# platform_designer_hps_system_hps_0_hps register map
Vendor: default_vendor.com; File version: 0.0
Registers are 32-bit, read-write, reset 0x0 unless marked. A register's access mark holds for its fields unless they carry their own. Offsets are from the block's base; [hi:lo] are bit positions; {n}, {i} and the like mark numbered series; 'fields as' and 'values as' point back to an identical list.

## sysmgr (part 1 of 3) — Registers in the System Manager module
Base 0xFFD08000
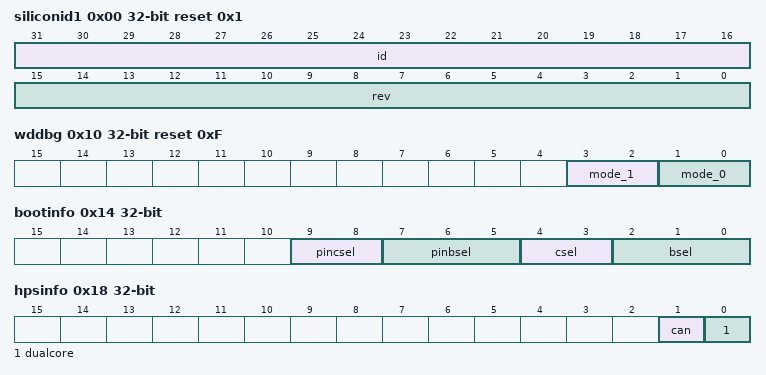
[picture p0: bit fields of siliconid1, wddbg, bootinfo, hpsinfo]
0x00 siliconid1 ro reset 0x1 — Specifies Silicon ID and revision number.
  [31:16] id — Silicon ID
    0=HPS_CycloneV_ArriaV
  [15:0] rev — Silicon revision number.
0x04 siliconid2 ro — Reserved for future use.
  [31:0] rsv
0x10 wddbg reset 0xF — Controls the behavior of the L4 watchdogs when the CPUs are in debug mode. These control registers are used to drive the pause input signal of the L4 watchdogs. Note that the watchdogs built into the MPU automatically are paused when their associated CPU enters debug mode. Only reset by a cold reset.
  [3:2] mode_1 — Controls behavior of L4 watchdog when CPUs in debug mode. Field array index matches L4 watchdog index.
    0=Continue; 1=PauseCPU0; 2=PauseCPU1; 3=PauseEither
  [1:0] mode_0 — Controls behavior of L4 watchdog when CPUs in debug mode. Field array index matches L4 watchdog index.
    0=Continue; 1=PauseCPU0; 2=PauseCPU1; 3=PauseEither
0x14 bootinfo ro (reset mask 0xFFFE0000) — Provides access to boot configuration information.
  [9:8] pincsel — Specifies the sampled value of the HPS CSEL pins. The value of HPS CSEL pins are sampled upon deassertion of cold reset.
  [7:5] pinbsel — Specifies the sampled value of the HPS BSEL pins. The value of HPS BSEL pins are sampled upon deassertion of cold reset.
  [4:3] csel — The clock select field specifies clock information for booting. The clock select encoding is a function of the CSEL value. The clock select field is read by the Boot ROM code on a cold or warm reset when booting from a flash device to get information about how to setup the HPS clocking to boot from the specified clock device. The encoding of the clock select field is specified by the enum associated with this field. The HPS CSEL pins value are sampled upon deassertion of cold reset.
  [2:0] bsel — The boot select field specifies the boot source. It is read by the Boot ROM code on a cold or warm reset to determine the boot source. The HPS BSEL pins value are sampled upon deassertion of cold reset.
    1=FPGA; 2=NAND_Flash_1_8v; 3=NAND_Flash_3_0v; 4=SD_MMC_EXTERNAL_TRANSCEIVER_1_8v; 5=SD_MMC_INTERNAL_TRANSCEIVER_3_0v; 6=QSPI_Flash_1_8v; 7=QSPI_Flash_3_0v
0x18 hpsinfo ro (reset mask 0xFFFFFFFC) — Provides information about the HPS capabilities.
  [1] can — Indicates if CAN0 and CAN1 controllers are available or not.
    0=CAN_UNAVAILABLE; 1=CAN_AVAILABLE
  [0] dualcore — Indicates if CPU1 is available in MPU or not.
    0=SingleCore; 1=DualCore
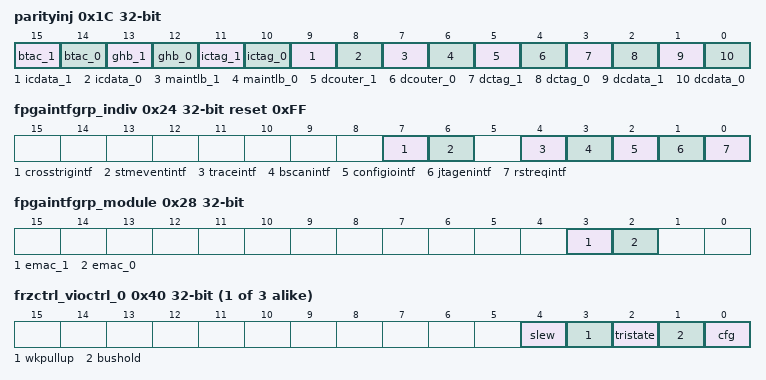
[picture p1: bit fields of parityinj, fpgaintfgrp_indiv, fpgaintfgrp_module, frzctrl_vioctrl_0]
0x1C parityinj — Inject parity failures into the parity-protected RAMs in the MPU. Allows software to test the parity failure interrupt handler. The field array index corresponds to the CPU index. All fields are reset by a cold or warm reset.
  [15] btac_1 — If 1, injecting parity error to BTAC RAM.The field array index corresponds to the CPU index.
  [14] btac_0 — If 1, injecting parity error to BTAC RAM.The field array index corresponds to the CPU index.
  [13] ghb_1 — If 1, injecting parity error to GHB RAM.The field array index corresponds to the CPU index.
  [12] ghb_0 — If 1, injecting parity error to GHB RAM.The field array index corresponds to the CPU index.
  [11] ictag_1 — If 1, injecting parity error to Instruction Cache Tag RAM.The field array index corresponds to the CPU index.
  [10] ictag_0 — If 1, injecting parity error to Instruction Cache Tag RAM.The field array index corresponds to the CPU index.
  [9] icdata_1 — If 1, injecting parity error to Instruction Cache Data RAM.The field array index corresponds to the CPU index.
  [8] icdata_0 — If 1, injecting parity error to Instruction Cache Data RAM.The field array index corresponds to the CPU index.
  [7] maintlb_1 — If 1, injecting parity error to Main TLB RAM.The field array index corresponds to the CPU index.
  [6] maintlb_0 — If 1, injecting parity error to Main TLB RAM.The field array index corresponds to the CPU index.
  [5] dcouter_1 — If 1, injecting parity error to Data Cache Outer RAM.The field array index corresponds to the CPU index.
  [4] dcouter_0 — If 1, injecting parity error to Data Cache Outer RAM.The field array index corresponds to the CPU index.
  [3] dctag_1 — If 1, injecting parity error to Data Cache Tag RAM.The field array index corresponds to the CPU index.
  [2] dctag_0 — If 1, injecting parity error to Data Cache Tag RAM.The field array index corresponds to the CPU index.
  [1] dcdata_1 — If 1, injecting parity error to Data Cache Data RAM.The field array index corresponds to the CPU index.
  [0] dcdata_0 — If 1, injecting parity error to Data Cache Data RAM.The field array index corresponds to the CPU index.
0x20 fpgaintfgrp_gbl reset 0x1 — Used to disable all interfaces between the FPGA and HPS.
  [0] intf — Used to disable all interfaces between the FPGA and HPS. Software must ensure that all interfaces between the FPGA and HPS are inactive before disabling them.
    0=Disable; 1=Enable
0x24 fpgaintfgrp_indiv reset 0xFF — Used to disable individual interfaces between the FPGA and HPS.
  [all] fields
    0=Disable; 1=Enable
  [7] crosstrigintf — Used to disable the FPGA Fabric from sending triggers to HPS debug logic. Note that this doesn't prevent the HPS debug logic from sending triggers to the FPGA Fabric.
  [6] stmeventintf — Used to disable the STM event interface. This interface allows logic in the FPGA fabric to trigger events to the STM debug module in the HPS.
  [4] traceintf — Used to disable the trace interface. This interface allows the HPS debug logic to send trace data to logic in the FPGA fabric.
  [3] bscanintf — Used to disable the boundary-scan interface. This interface allows the FPGA JTAG TAP controller to execute boundary-scan instructions such as SAMPLE/PRELOAD, EXTEST, and HIGHZ. The boundary-scan interface must be enabled before attempting to send the boundary-scan instructions to the FPGA JTAG TAP controller.
  [2] configiointf — Used to disable the CONFIG_IO interface. This interface allows the FPGA JTAG TAP controller to execute the CONFIG_IO instruction and configure all device I/Os (FPGA and HPS). This is typically done before executing boundary-scan instructions. The CONFIG_IO interface must be enabled before attempting to send the CONFIG_IO instruction to the FPGA JTAG TAP controller.
  [1] jtagenintf — Used to disable the JTAG enable interface. This interface allows logic in the FPGA fabric to disable the HPS JTAG operation.
  [0] rstreqintf — Used to disable the reset request interface. This interface allows logic in the FPGA fabric to request HPS resets. This field disables the following reset request signals from the FPGA fabric to HPS:[list][*]f2h_cold_rst_req_n - Triggers a cold reset of the HPS[*]f2h_warm_rst_req_n - Triggers a warm reset of the HPS[*]f2h_dbg_rst_req_n - Triggers a debug reset of the HPS[/list]
0x28 fpgaintfgrp_module — Used to disable signals from the FPGA fabric to individual HPS modules.
  [3] emac_1 — Used to disable signals from the FPGA fabric to the EMAC modules that could potentially interfere with their normal operation. The array index corresponds to the EMAC module instance.
    0=Disable; 1=Enable
  [2] emac_0 — Used to disable signals from the FPGA fabric to the EMAC modules that could potentially interfere with their normal operation. The array index corresponds to the EMAC module instance.
    0=Disable; 1=Enable
0x30 scanmgrgrp_ctrl — Controls behaviors of Scan Manager not controlled by registers in the Scan Manager itself.
  [0] fpgajtagen — Controls whether FPGA JTAG pins or Scan Manager drives JTAG signals to the FPGA. Only reset by a cold reset (ignores warm reset).
    0=Fpgapins; 1=Scanmgr
{0x40+4i} frzctrl_vioctrl_{i} (i=0..2) — Used to drive freeze signals to HPS VIO banks. The register array index corresponds to the freeze channel. Freeze channel 0 provides freeze signals to VIO bank 0 and 1. Freeze channel 1 provides freeze signals to VIO bank 2 and 3. Only drives freeze signals when SRC.VIO1 is set to SW. Freeze channel 2 provides freeze signals to VIO bank 4. All fields are only reset by a cold reset (ignore warm reset). The following equation determines when the weak pullup resistor is enabled: enabled = ~wkpullup | (CFF & cfg & tristate) where CFF is the value of weak pullup as set by IO configuration
  [4] slew — Controls IO slew-rate
    0=Slow; 1=Cfg
  [3] wkpullup — Controls weak pullup resistor
    0=Enable; 1=Cfg
  [2] tristate — Controls IO tri-state
    0=Enable; 1=Cfg
  [1] bushold — Controls bus hold circuit
    0=Disable; 1=Cfg
  [0] cfg — Controls IO configuration
    0=Disable; 1=Cfg
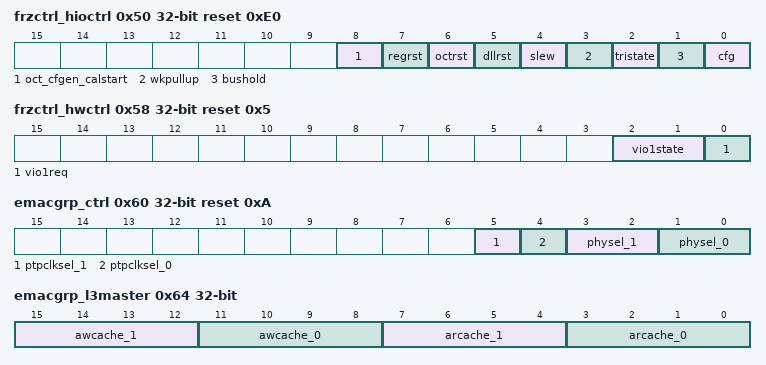
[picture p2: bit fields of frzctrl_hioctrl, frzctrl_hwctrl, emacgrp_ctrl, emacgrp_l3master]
0x50 frzctrl_hioctrl reset 0xE0 — Used to drive freeze signals to HPS HIO bank (DDR SDRAM). All fields are only reset by a cold reset (ignore warm reset). The following equation determines when the weak pullup resistor is enabled: enabled = ~wkpullup | (CFF & cfg & tristate) where CFF is the value of weak pullup as set by IO configuration
  [8] oct_cfgen_calstart — Controls OCT calibration and OCT IO configuration enable.
    0=Disable; 1=Enable
  [7] regrst — Controls IO and DQS reset.
    0=Disable; 1=Enable
  [6] octrst — Controls OCT reset.
    0=Disable; 1=Enable
  [5] dllrst — Controls DLL (Delay-Locked Loop) reset.
    0=Disable; 1=Enable
  [4] slew — Controls IO slew-rate
    0=Slow; 1=Cfg
  [3] wkpullup — Controls weak pullup resistor
    0=Enable; 1=Cfg
  [2] tristate — Controls IO tri-state
    0=Enable; 1=Cfg
  [1] bushold — Controls bus hold circuit
    0=Disable; 1=Cfg
  [0] cfg — Controls IO configuration
    0=Disable; 1=Cfg
0x54 frzctrl_src — Contains register field to choose between software state machine (vioctrl array index [1] register) or hardware state machine in the Freeze Controller as the freeze signal source for VIO channel 1. All fields are only reset by a cold reset (ignore warm reset).
  [0] vio1 — The freeze signal source for VIO channel 1 (VIO bank 2 and bank 3).
    0=sw; 1=hw
0x58 frzctrl_hwctrl reset 0x5 — Activate freeze or thaw operations on VIO channel 1 (HPS IO bank 2 and bank 3) and monitor for completeness and the current state. These fields interact with the hardware state machine in the Freeze Controller. These fields can be accessed independent of the value of SRC1.VIO1 although they only have an effect on the VIO channel 1 freeze signals when SRC1.VIO1 is setup to have the hardware state machine be the freeze signal source. All fields are only reset by a cold reset (ignore warm reset).
  [2:1] vio1state ro — Software reads this field to determine the current frozen/thawed state of the VIO channel 1 or to determine when a freeze/thaw request is made by writing the corresponding *REQ field in this register has completed. Reset by a cold reset (ignores warm reset).
    0=Thawed2Frozen; 1=Thawed; 2=Frozen; 3=Frozen2Thawed
  [0] vio1req — Requests hardware state machine to generate freeze signal sequence to transition between frozen and thawed states. If this field is read by software, it contains the value previously written by software (i.e. this field is not written by hardware).
    0=ReqThaw; 1=ReqFrz
0x60 emacgrp_ctrl reset 0xA — Registers used by the EMACs. All fields are reset by a cold or warm reset.
  [5] ptpclksel_1 — Selects the source of the 1588 PTP reference clock. This is sampled by an EMAC module when it exits from reset. The field array index corresponds to the EMAC index.
    0=OSC1_CLK; 1=FPGA_PTP_REF_CLK
  [4] ptpclksel_0 — Selects the source of the 1588 PTP reference clock. This is sampled by an EMAC module when it exits from reset. The field array index corresponds to the EMAC index.
    0=OSC1_CLK; 1=FPGA_PTP_REF_CLK
  [3:2] physel_1 — Controls the PHY interface selection of the EMACs. This is sampled by an EMAC module when it exits from reset. The associated enum defines the allowed values. The field array index corresponds to the EMAC index.
    0=GMII_MII; 1=RGMII; 2=RMII
  [1:0] physel_0 — Controls the PHY interface selection of the EMACs. This is sampled by an EMAC module when it exits from reset. The associated enum defines the allowed values. The field array index corresponds to the EMAC index.
    0=GMII_MII; 1=RGMII; 2=RMII
0x64 emacgrp_l3master — Controls the L3 master ARCACHE and AWCACHE AXI signals. These register bits should be updated only during system initialization prior to removing the peripheral from reset. They may not be changed dynamically during peripheral operation All fields are reset by a cold or warm reset.
  [all] fields
    0=Noncache_Nonbuff; 1=Buff; 2=Cache_Nonalloc; 3=Cache_Buff_Nonalloc; 6=Cache_Wrthru_Rdalloc; 7=Cache_Wrback_Rdalloc; 10=Cache_Wrthru_Wralloc; 11=Cache_Wrback_Wralloc; 14=Cache_Wrthru_Alloc; 15=Cache_Wrback_Alloc
  [15:12] awcache_1 — Specifies the values of the 2 EMAC AWCACHE signals. The field array index corresponds to the EMAC index.
  [11:8] awcache_0 — Specifies the values of the 2 EMAC AWCACHE signals. The field array index corresponds to the EMAC index.
  [7:4] arcache_1 — Specifies the values of the 2 EMAC ARCACHE signals. The field array index corresponds to the EMAC index.
  [3:0] arcache_0 — Specifies the values of the 2 EMAC ARCACHE signals. The field array index corresponds to the EMAC index.
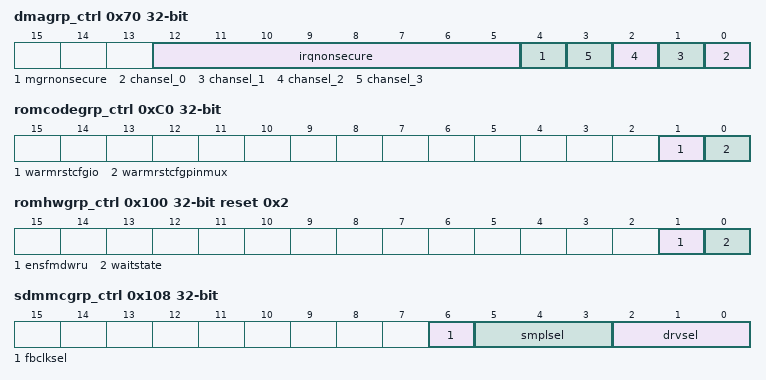
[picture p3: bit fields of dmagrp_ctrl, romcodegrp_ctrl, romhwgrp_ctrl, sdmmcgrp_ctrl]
0x70 dmagrp_ctrl — Registers used by the DMA Controller. All fields are reset by a cold or warm reset. These register bits should be updated during system initialization prior to removing the DMA controller from reset. They may not be changed dynamically during DMA operation.
  [12:5] irqnonsecure — Specifies the security state of an event-interrupt resource. If bit index [x] is 0, the DMAC assigns event<x> or irq[x] to the Secure state. If bit index [x] is 1, the DMAC assigns event<x> or irq[x] to the Non-secure state.
  [4] mgrnonsecure — Specifies the security state of the DMA manager thread. 0 = assigns DMA manager to the Secure state. 1 = assigns DMA manager to the Non-secure state. Sampled by the DMA controller when it exits from reset.
  [n] chansel_{n} (n=0..3) — Controls mux that selects whether FPGA or CAN connects to one of the DMA peripheral request interfaces.The peripheral request interface index equals the array index + 4. For example, array index 0 is for peripheral request index 4.
    0=FPGA; 1=CAN
0x74 dmagrp_persecurity — Controls the security state of a peripheral request interface. Sampled by the DMA controller when it exits from reset. These register bits should be updated during system initialization prior to removing the DMA controller from reset. They may not be changed dynamically during DMA operation.
  [31:0] nonsecure — If bit index [x] is 0, the DMA controller assigns peripheral request interface x to the Secure state. If bit index [x] is 1, the DMA controller assigns peripheral request interface x to the Non-secure state. Reset by a cold or warm reset.
{0x80+4i} iswgrp_handoff_{i} (i=0..7) — These registers are used to store handoff infomation between the preloader and the OS. These 8 registers can be used to store any information. The contents of these registers have no impact on the state of the HPS hardware.
  [31:0] value — Preloader Handoff Information.
0xC0 romcodegrp_ctrl — Contains information used to control Boot ROM code.
  [1] warmrstcfgio — Specifies whether the Boot ROM code configures the IOs used by boot after a warm reset. Note that the Boot ROM code always configures the IOs used by boot after a cold reset. After the Boot ROM code configures the IOs used by boot, it always disables this field. It is up to user software to enable this field if it wants a different behavior.
    0=disabled; 1=enabled
  [0] warmrstcfgpinmux — Specifies whether the Boot ROM code configures the pin mux for boot pins after a warm reset. Note that the Boot ROM code always configures the pin mux for boot pins after a cold reset. After the Boot ROM code configures the pin mux for boot pins, it always disables this field. It is up to user software to enable this field if it wants a different behavior.
    0=disabled; 1=enabled
0xC4 romcodegrp_cpu1startaddr — When CPU1 is released from reset and the Boot ROM is located at the CPU1 reset exception address (the typical case), the Boot ROM reset handler code reads the address stored in this register and jumps it to hand off execution to user software.
  [31:0] value — Address for CPU1 to start executing at after coming out of reset.
0xC8 romcodegrp_initswstate — The preloader software (loaded by the Boot ROM) writes the magic value 0x49535756 (ISWV in ASCII) to this register when it has reached a valid state.
  [31:0] value — Written with magic value.
    0=Invalid; 0x49535756=Valid
0xCC romcodegrp_initswlastld — Contains the index of the last preloader software image loaded by the Boot ROM from the boot device.
  [1:0] index — Index of last image loaded.
0xD0 romcodegrp_bootromswstate — 32-bits general purpose register used by the Boot ROM code. Actual usage is defined in the Boot ROM source code.
  [31:0] value — Reserved for Boot ROM use.
0xE0 romcodegrp_warmramgrp_enable — Enables or disables the warm reset from On-chip RAM feature.
  [31:0] magic — Controls whether Boot ROM will attempt to boot from the contents of the On-chip RAM on a warm reset. When this feature is enabled, the Boot ROM code will not configure boot IOs, the pin mux, or clocks. Note that the enable value is a 32-bit magic value (provided by the enum).
    0=disabled; 0xAE9EFEBC=enabled
0xE4 romcodegrp_warmramgrp_datastart — Offset into On-chip RAM of the start of the region for CRC validation
  [15:0] offset — Contains the byte offset into the On-chip RAM of the start of the On-chip RAM region for the warm boot CRC validation. The offset must be an integer multiple of 4 (i.e. aligned to a word). The Boot ROM code will set the top 16 bits to 0xFFFF and clear the bottom 2 bits.
0xE8 romcodegrp_warmramgrp_length — Length of region in On-chip RAM for CRC validation.
  [15:0] size — Contains the length (in bytes) of the region in the On-chip RAM for the warm boot CRC validation. If the length is 0, the Boot ROM won't perform CRC calculation and CRC check to avoid overhead caused by CRC validation. If the START + LENGTH exceeds the maximum offset into the On-chip RAM, the Boot ROM won't boot from the On-chip RAM. The length must be an integer multiple of 4. The Boot ROM code will clear the top 16 bits and the bottom 2 bits.
0xEC romcodegrp_warmramgrp_execution — Offset into On-chip RAM to enter to on a warm boot.
  [15:0] offset — Contains the byte offset into the On-chip RAM that the Boot ROM will jump to if the CRC validation succeeds. The Boot ROM code will set the top 16 bits to 0xFFFF.
0xF0 romcodegrp_warmramgrp_crc reset 0xE763552A — Length of region in On-chip RAM for CRC validation.
  [31:0] expected — Contains the expected CRC of the region in the On-chip RAM.The Boot ROM code calculates the actual CRC for all bytes in the region specified by the DATA START an LENGTH registers. The contents of the EXECUTION register (after it has been read and modified by the Boot ROM code) is also included in the CRC calculation. The contents of the EXECUTION register is added to the CRC accumulator a byte at a time starting with the least significant byte. If the actual CRC doesn't match the expected CRC value in this register, the Boot ROM won't boot from the On-chip RAM. The CRC is a standard CRC32 with the polynomial: x^32 + x^26 + x^23 + x^22 + x^16 + x^12 + x^11 + x^10 + x^8 + x^7 + x^5 + x^4 + x^2 + x + 1 There is no reflection of the bits and the initial value of the remainder is 0xFFFFFFFF and the final value is exclusive ORed with 0xFFFFFFFF.
0x100 romhwgrp_ctrl reset 0x2 — Controls behavior of Boot ROM hardware. All fields are only reset by a cold reset (ignore warm reset).
  [1] ensfmdwru — Controls whether the wait state bit is updated upon deassertion of warm reset. This field is set on a cold reset.
    0=Disable; 1=Enable
  [0] waitstate — Controls the number of wait states applied to the Boot ROM's read operation. This field is cleared on a cold reset and optionally updated by hardware upon deassertion of warm reset.
    0=Disable; 1=Enable
0x108 sdmmcgrp_ctrl — Registers used by the SDMMC Controller. All fields are reset by a cold or warm reset.
  [6] fbclksel — Select which fb_clk to be used as cclk_in_sample. If 0, cclk_in_sample is driven by internal phase shifted cclk_in. If 1, cclk_in_sample is driven by fb_clk_in. No phase shifting is provided internally on cclk_in_sample. Note: Using the feedback clock (setting this bit to 1) is not a supported use model.
  [5:3] smplsel — Select which phase shift of the clock for cclk_in_sample.
    0=degrees0; 1=degrees45; 2=degrees90; 3=degrees135; 4=degrees180; 5=degrees225; 6=degrees270; 7=degrees315
  [2:0] drvsel — Select which phase shift of the clock for cclk_in_drv.
    values as smplsel
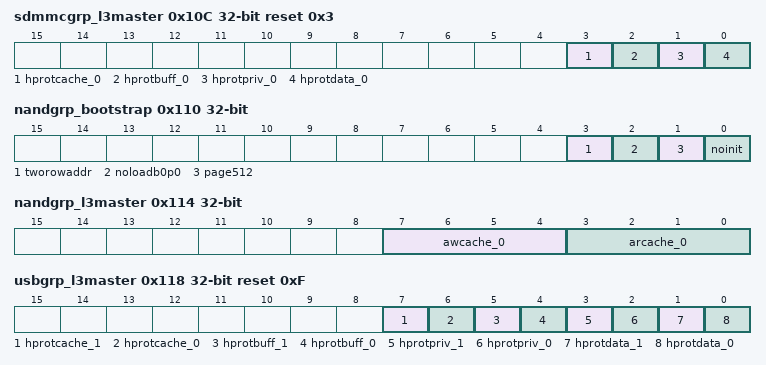
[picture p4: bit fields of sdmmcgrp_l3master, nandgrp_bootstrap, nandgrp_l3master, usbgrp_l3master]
0x10C sdmmcgrp_l3master reset 0x3 — Controls the L3 master HPROT AHB-Lite signal. These register bits should be updated only during system initialization prior to removing the peripheral from reset. They may not be changed dynamically during peripheral operation All fields are reset by a cold or warm reset.
  [3] hprotcache_0 — If 1, L3 master accesses for the SD/MMC module are cacheable.
  [2] hprotbuff_0 — If 1, L3 master accesses for the SD/MMC module are bufferable.
  [1] hprotpriv_0 — If 1, L3 master accesses for the SD/MMC module are privileged.
  [0] hprotdata_0 — Specifies if the L3 master access is for data or opcode for the SD/MMC module.
    0=Opcode; 1=Data
0x110 nandgrp_bootstrap — Bootstrap fields sampled by NAND Flash Controller when released from reset. All fields are reset by a cold or warm reset.
  [3] tworowaddr — If 1, NAND device requires only 2 row address cycles instead of the normal 3 row address cycles.
  [2] noloadb0p0 — If 1, inhibits NAND Flash Controller from loading page 0 of block 0 of the NAND device as part of the initialization procedure.
  [1] page512 — If 1, NAND device has a 512 byte page size.
  [0] noinit — If 1, inhibits NAND Flash Controller from performing initialization when coming out of reset. Instead, software must program all registers pertaining to device parameters like page size, width, etc.
0x114 nandgrp_l3master — Controls the L3 master ARCACHE and AWCACHE AXI signals. These register bits should be updated only during system initialization prior to removing the peripheral from reset. They may not be changed dynamically during peripheral operation All fields are reset by a cold or warm reset.
  [7:4] awcache_0 — Specifies the value of the module AWCACHE signal.
    values as the fields of emacgrp_l3master
  [3:0] arcache_0 — Specifies the value of the module ARCACHE signal.
    values as the fields of emacgrp_l3master
0x118 usbgrp_l3master reset 0xF — Controls the L3 master HPROT AHB-Lite signal. These register bits should be updated only during system initialization prior to removing the peripheral from reset. They may not be changed dynamically during peripheral operation All fields are reset by a cold or warm reset.
  [7] hprotcache_1 — If 1, L3 master accesses for the USB modules are cacheable. The field array index corresponds to the USB index.
  [6] hprotcache_0 — If 1, L3 master accesses for the USB modules are cacheable. The field array index corresponds to the USB index.
  [5] hprotbuff_1 — If 1, L3 master accesses for the USB modules are bufferable. The field array index corresponds to the USB index.
  [4] hprotbuff_0 — If 1, L3 master accesses for the USB modules are bufferable. The field array index corresponds to the USB index.
  [3] hprotpriv_1 — If 1, L3 master accesses for the USB modules are privileged. The field array index corresponds to the USB index.
  [2] hprotpriv_0 — If 1, L3 master accesses for the USB modules are privileged. The field array index corresponds to the USB index.
  [1] hprotdata_1 — Specifies if the L3 master access is for data or opcode for the USB modules. The field array index corresponds to the USB index.
    0=Opcode; 1=Data
  [0] hprotdata_0 — Specifies if the L3 master access is for data or opcode for the USB modules. The field array index corresponds to the USB index.
    0=Opcode; 1=Data
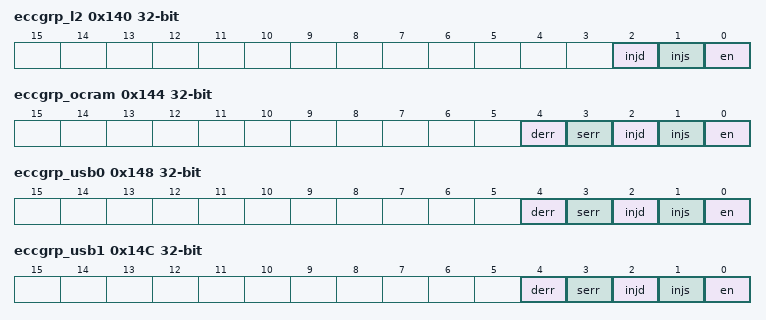
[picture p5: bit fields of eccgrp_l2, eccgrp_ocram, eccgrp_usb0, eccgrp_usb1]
0x140 eccgrp_l2 — This register is used to enable ECC on the L2 Data RAM. ECC errors can be injected into the write path using bits in this register. This register contains interrupt status of the ECC single/double bit error. Only reset by a cold reset (ignores warm reset).
  [2] injd — Changing this bit from zero to one injects a double, non-correctable error into the L2 Data RAM. This only injects one double bit error into the L2 Data RAM.
  [1] injs — Changing this bit from zero to one injects a single, correctable error into the L2 Data RAM. This only injects one error into the L2 Data RAM.
  [0] en — Enable ECC for L2 Data RAM
0x144 eccgrp_ocram — This register is used to enable ECC on the On-chip RAM. ECC errors can be injected into the write path using bits in this register. This register contains interrupt status of the ECC single/double bit error. Only reset by a cold reset (ignores warm reset).
  [4] derr write-1-clears — This bit is an interrupt status bit for On-chip RAM ECC double bit, non-correctable error. It is set by hardware when double bit, non-correctable error occurs in On-chip RAM. Software needs to write 1 into this bit to clear the interrupt status.
  [3] serr write-1-clears — This bit is an interrupt status bit for On-chip RAM ECC single, correctable error. It is set by hardware when single, correctable error occurs in On-chip RAM. Software needs to write 1 into this bit to clear the interrupt status.
  [2] injd — Changing this bit from zero to one injects a double, non-correctable error into the On-chip RAM. This only injects one double bit error into the On-chip RAM.
  [1] injs — Changing this bit from zero to one injects a single, correctable error into the On-chip RAM. This only injects one error into the On-chip RAM.
  [0] en — Enable ECC for On-chip RAM
0x148 eccgrp_usb0 — This register is used to enable ECC on the USB0 RAM. ECC errors can be injected into the write path using bits in this register. This register contains interrupt status of the ECC single/double bit error. Only reset by a cold reset (ignores warm reset).
  [4] derr write-1-clears — This bit is an interrupt status bit for USB0 RAM ECC double bit, non-correctable error. It is set by hardware when double bit, non-correctable error occurs in USB0 RAM. Software needs to write 1 into this bit to clear the interrupt status.
  [3] serr write-1-clears — This bit is an interrupt status bit for USB0 RAM ECC single, correctable error. It is set by hardware when single, correctable error occurs in USB0 RAM. Software needs to write 1 into this bit to clear the interrupt status.
  [2] injd — Changing this bit from zero to one injects a double, non-correctable error into the USB0 RAM. This only injects one double bit error into the USB0 RAM.
  [1] injs — Changing this bit from zero to one injects a single, correctable error into the USB0 RAM. This only injects one error into the USB0 RAM.
  [0] en — Enable ECC for USB0 RAM
0x14C eccgrp_usb1 — This register is used to enable ECC on the USB1 RAM. ECC errors can be injected into the write path using bits in this register. This register contains interrupt status of the ECC single/double bit error. Only reset by a cold reset (ignores warm reset).
  [4] derr write-1-clears — This bit is an interrupt status bit for USB1 RAM ECC double bit, non-correctable error. It is set by hardware when double bit, non-correctable error occurs in USB1 RAM. Software needs to write 1 into this bit to clear the interrupt status.
  [3] serr write-1-clears — This bit is an interrupt status bit for USB1 RAM ECC single, correctable error. It is set by hardware when single, correctable error occurs in USB1 RAM. Software needs to write 1 into this bit to clear the interrupt status.
  [2] injd — Changing this bit from zero to one injects a double, non-correctable error into the USB1 RAM. This only injects one double bit error into the USB1 RAM.
  [1] injs — Changing this bit from zero to one injects a single, correctable error into the USB1 RAM. This only injects one error into the USB1 RAM.
  [0] en — Enable ECC for USB1 RAM
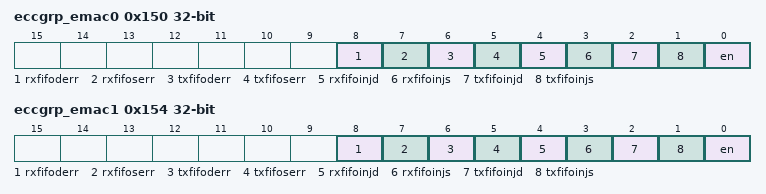
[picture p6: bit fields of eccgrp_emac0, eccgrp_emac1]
0x150 eccgrp_emac0 — This register is used to enable ECC on the EMAC0 RAM. ECC errors can be injected into the write path using bits in this register. This register contains interrupt status of the ECC single/double bit error. Only reset by a cold reset (ignores warm reset).
  [8] rxfifoderr write-1-clears — This bit is an interrupt status bit for EMAC0 RXFIFO RAM ECC double bit, non-correctable error. It is set by hardware when double bit, non-correctable error occurs in EMAC0 RXFIFO RAM. Software needs to write 1 into this bit to clear the interrupt status.
  [7] rxfifoserr write-1-clears — This bit is an interrupt status bit for EMAC0 RXFIFO RAM ECC single, correctable error. It is set by hardware when single, correctable error occurs in EMAC0 RXFIFO RAM. Software needs to write 1 into this bit to clear the interrupt status.
  [6] txfifoderr write-1-clears — This bit is an interrupt status bit for EMAC0 TXFIFO RAM ECC double bit, non-correctable error. It is set by hardware when double bit, non-correctable error occurs in EMAC0 TXFIFO RAM. Software needs to write 1 into this bit to clear the interrupt status.
  [5] txfifoserr write-1-clears — This bit is an interrupt status bit for EMAC0 TXFIFO RAM ECC single, correctable error. It is set by hardware when single, correctable error occurs in EMAC0 TXFIFO RAM. Software needs to write 1 into this bit to clear the interrupt status.
  [4] rxfifoinjd — Changing this bit from zero to one injects a double, non-correctable error into the EMAC0 RXFIFO RAM. This only injects one double bit error into the EMAC0 RXFIFO RAM.
  [3] rxfifoinjs — Changing this bit from zero to one injects a single, correctable error into the EMAC0 RXFIFO RAM. This only injects one error into the EMAC0 RXFIFO RAM.
  [2] txfifoinjd — Changing this bit from zero to one injects a double, non-correctable error into the EMAC0 TXFIFO RAM. This only injects one double bit error into the EMAC0 TXFIFO RAM.
  [1] txfifoinjs — Changing this bit from zero to one injects a single, correctable error into the EMAC0 TXFIFO RAM. This only injects one error into the EMAC0 TXFIFO RAM.
  [0] en — Enable ECC for EMAC0 RAM
0x154 eccgrp_emac1 — This register is used to enable ECC on the EMAC1 RAM. ECC errors can be injected into the write path using bits in this register. This register contains interrupt status of the ECC single/double bit error. Only reset by a cold reset (ignores warm reset).
  [8] rxfifoderr write-1-clears — This bit is an interrupt status bit for EMAC1 RXFIFO RAM ECC double bit, non-correctable error. It is set by hardware when double bit, non-correctable error occurs in EMAC1 RXFIFO RAM. Software needs to write 1 into this bit to clear the interrupt status.
  [7] rxfifoserr write-1-clears — This bit is an interrupt status bit for EMAC1 RXFIFO RAM ECC single, correctable error. It is set by hardware when single, correctable error occurs in EMAC1 RXFIFO RAM. Software needs to write 1 into this bit to clear the interrupt status.
  [6] txfifoderr write-1-clears — This bit is an interrupt status bit for EMAC1 TXFIFO RAM ECC double bit, non-correctable error. It is set by hardware when double bit, non-correctable error occurs in EMAC1 TXFIFO RAM. Software needs to write 1 into this bit to clear the interrupt status.
  [5] txfifoserr write-1-clears — This bit is an interrupt status bit for EMAC1 TXFIFO RAM ECC single, correctable error. It is set by hardware when single, correctable error occurs in EMAC1 TXFIFO RAM. Software needs to write 1 into this bit to clear the interrupt status.
  [4] rxfifoinjd — Changing this bit from zero to one injects a double, non-correctable error into the EMAC1 RXFIFO RAM. This only injects one double bit error into the EMAC1 RXFIFO RAM.
  [3] rxfifoinjs — Changing this bit from zero to one injects a single, correctable error into the EMAC1 RXFIFO RAM. This only injects one error into the EMAC1 RXFIFO RAM.
  [2] txfifoinjd — Changing this bit from zero to one injects a double, non-correctable error into the EMAC1 TXFIFO RAM. This only injects one double bit error into the EMAC1 TXFIFO RAM.
  [1] txfifoinjs — Changing this bit from zero to one injects a single, correctable error into the EMAC1 TXFIFO RAM. This only injects one error into the EMAC1 TXFIFO RAM.
  [0] en — Enable ECC for EMAC1 RAM
